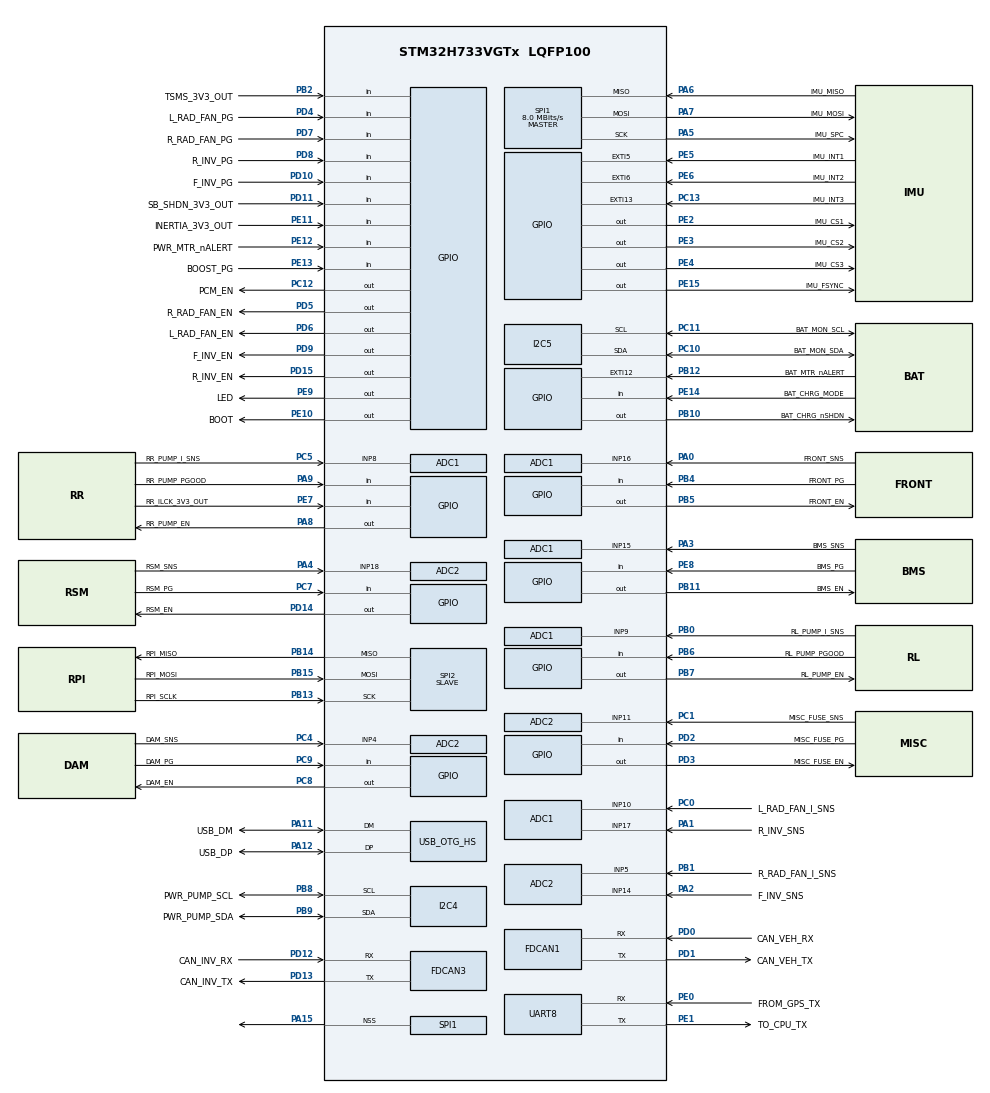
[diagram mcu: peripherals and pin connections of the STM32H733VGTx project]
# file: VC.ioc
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ADC1.Channel-1\#ChannelRegularConversion=ADC_CHANNEL_8
ADC1.Channel-2\#ChannelRegularConversion=ADC_CHANNEL_9
ADC1.Channel-3\#ChannelRegularConversion=ADC_CHANNEL_10
ADC1.Channel-4\#ChannelRegularConversion=ADC_CHANNEL_15
ADC1.Channel-5\#ChannelRegularConversion=ADC_CHANNEL_16
ADC1.Channel-6\#ChannelRegularConversion=ADC_CHANNEL_17
ADC1.ClockPrescaler=ADC_CLOCK_ASYNC_DIV4
ADC1.ConversionDataManagement=ADC_CONVERSIONDATA_DMA_CIRCULAR
ADC1.EOCSelection=ADC_EOC_SINGLE_CONV
ADC1.ExternalTrigConv=ADC_EXTERNALTRIG_T3_TRGO
ADC1.NbrOfConversion=6
ADC1.NbrOfConversionFlag=1
ADC1.OffsetNumber-1\#ChannelRegularConversion=ADC_OFFSET_NONE
ADC1.OffsetNumber-2\#ChannelRegularConversion=ADC_OFFSET_NONE
ADC1.OffsetNumber-3\#ChannelRegularConversion=ADC_OFFSET_NONE
ADC1.OffsetNumber-4\#ChannelRegularConversion=ADC_OFFSET_NONE
ADC1.OffsetNumber-5\#ChannelRegularConversion=ADC_OFFSET_NONE
ADC1.OffsetNumber-6\#ChannelRegularConversion=ADC_OFFSET_NONE
ADC1.OffsetSignedSaturation-1\#ChannelRegularConversion=DISABLE
ADC1.OffsetSignedSaturation-2\#ChannelRegularConversion=DISABLE
ADC1.OffsetSignedSaturation-3\#ChannelRegularConversion=DISABLE
ADC1.OffsetSignedSaturation-4\#ChannelRegularConversion=DISABLE
ADC1.OffsetSignedSaturation-5\#ChannelRegularConversion=DISABLE
ADC1.OffsetSignedSaturation-6\#ChannelRegularConversion=DISABLE
ADC1.Rank-1\#ChannelRegularConversion=1
ADC1.Rank-2\#ChannelRegularConversion=2
ADC1.Rank-3\#ChannelRegularConversion=3
ADC1.Rank-4\#ChannelRegularConversion=4
ADC1.Rank-5\#ChannelRegularConversion=5
ADC1.Rank-6\#ChannelRegularConversion=6
ADC1.SamplingTime-1\#ChannelRegularConversion=ADC_SAMPLETIME_32CYCLES_5
ADC1.SamplingTime-2\#ChannelRegularConversion=ADC_SAMPLETIME_32CYCLES_5
ADC1.SamplingTime-3\#ChannelRegularConversion=ADC_SAMPLETIME_32CYCLES_5
ADC1.SamplingTime-4\#ChannelRegularConversion=ADC_SAMPLETIME_32CYCLES_5
ADC1.SamplingTime-5\#ChannelRegularConversion=ADC_SAMPLETIME_32CYCLES_5
ADC1.SamplingTime-6\#ChannelRegularConversion=ADC_SAMPLETIME_32CYCLES_5
ADC1.master=1
ADC2.Channel-1\#ChannelRegularConversion=ADC_CHANNEL_4
ADC2.Channel-2\#ChannelRegularConversion=ADC_CHANNEL_5
ADC2.Channel-3\#ChannelRegularConversion=ADC_CHANNEL_11
ADC2.Channel-4\#ChannelRegularConversion=ADC_CHANNEL_14
ADC2.Channel-5\#ChannelRegularConversion=ADC_CHANNEL_18
ADC2.ClockPrescaler=ADC_CLOCK_ASYNC_DIV4
ADC2.ConversionDataManagement=ADC_CONVERSIONDATA_DMA_CIRCULAR
ADC2.EOCSelection=ADC_EOC_SEQ_CONV
ADC2.ExternalTrigConv=ADC_EXTERNALTRIG_T3_TRGO
ADC2.NbrOfConversion=5
ADC2.NbrOfConversionFlag=1
ADC2.OffsetNumber-1\#ChannelRegularConversion=ADC_OFFSET_NONE
ADC2.OffsetNumber-2\#ChannelRegularConversion=ADC_OFFSET_NONE
ADC2.OffsetNumber-3\#ChannelRegularConversion=ADC_OFFSET_NONE
ADC2.OffsetNumber-4\#ChannelRegularConversion=ADC_OFFSET_NONE
ADC2.OffsetNumber-5\#ChannelRegularConversion=ADC_OFFSET_NONE
ADC2.OffsetSignedSaturation-1\#ChannelRegularConversion=DISABLE
ADC2.OffsetSignedSaturation-2\#ChannelRegularConversion=DISABLE
ADC2.OffsetSignedSaturation-3\#ChannelRegularConversion=DISABLE
ADC2.OffsetSignedSaturation-4\#ChannelRegularConversion=DISABLE
ADC2.OffsetSignedSaturation-5\#ChannelRegularConversion=DISABLE
ADC2.Rank-1\#ChannelRegularConversion=1
ADC2.Rank-2\#ChannelRegularConversion=2
ADC2.Rank-3\#ChannelRegularConversion=3
ADC2.Rank-4\#ChannelRegularConversion=4
ADC2.Rank-5\#ChannelRegularConversion=5
ADC2.SamplingTime-1\#ChannelRegularConversion=ADC_SAMPLETIME_32CYCLES_5
ADC2.SamplingTime-2\#ChannelRegularConversion=ADC_SAMPLETIME_32CYCLES_5
ADC2.SamplingTime-3\#ChannelRegularConversion=ADC_SAMPLETIME_32CYCLES_5
ADC2.SamplingTime-4\#ChannelRegularConversion=ADC_SAMPLETIME_32CYCLES_5
ADC2.SamplingTime-5\#ChannelRegularConversion=ADC_SAMPLETIME_32CYCLES_5
CORTEX_M7.CPU_ICache=Enabled
Dma.ADC1.0.Direction=DMA_PERIPH_TO_MEMORY
Dma.ADC1.0.EventEnable=DISABLE
Dma.ADC1.0.FIFOMode=DMA_FIFOMODE_DISABLE
Dma.ADC1.0.Instance=DMA1_Stream1
Dma.ADC1.0.MemDataAlignment=DMA_MDATAALIGN_HALFWORD
Dma.ADC1.0.MemInc=DMA_MINC_ENABLE
Dma.ADC1.0.Mode=DMA_CIRCULAR
Dma.ADC1.0.PeriphDataAlignment=DMA_PDATAALIGN_HALFWORD
Dma.ADC1.0.PeriphInc=DMA_PINC_DISABLE
Dma.ADC1.0.Polarity=HAL_DMAMUX_REQ_GEN_RISING
Dma.ADC1.0.Priority=DMA_PRIORITY_LOW
Dma.ADC1.0.RequestNumber=1
Dma.ADC1.0.SignalID=NONE
Dma.ADC1.0.SyncEnable=DISABLE
Dma.ADC1.0.SyncPolarity=HAL_DMAMUX_SYNC_NO_EVENT
Dma.ADC1.0.SyncRequestNumber=1
Dma.ADC1.0.SyncSignalID=NONE
Dma.ADC2.1.Direction=DMA_PERIPH_TO_MEMORY
Dma.ADC2.1.EventEnable=DISABLE
Dma.ADC2.1.FIFOMode=DMA_FIFOMODE_DISABLE
Dma.ADC2.1.Instance=DMA1_Stream2
Dma.ADC2.1.MemDataAlignment=DMA_MDATAALIGN_HALFWORD
Dma.ADC2.1.MemInc=DMA_MINC_ENABLE
Dma.ADC2.1.Mode=DMA_CIRCULAR
Dma.ADC2.1.PeriphDataAlignment=DMA_PDATAALIGN_HALFWORD
Dma.ADC2.1.PeriphInc=DMA_PINC_DISABLE
Dma.ADC2.1.Polarity=HAL_DMAMUX_REQ_GEN_RISING
Dma.ADC2.1.Priority=DMA_PRIORITY_LOW
Dma.ADC2.1.RequestNumber=1
Dma.ADC2.1.SignalID=NONE
Dma.ADC2.1.SyncEnable=DISABLE
Dma.ADC2.1.SyncPolarity=HAL_DMAMUX_SYNC_NO_EVENT
Dma.ADC2.1.SyncRequestNumber=1
Dma.ADC2.1.SyncSignalID=NONE
Dma.Request0=ADC1
Dma.Request1=ADC2
Dma.Request2=UART8_RX
Dma.Request3=SPI1_RX
Dma.Request4=SPI1_TX
Dma.SPI1_RX.3.Direction=DMA_PERIPH_TO_MEMORY
Dma.SPI1_RX.3.EventEnable=DISABLE
Dma.SPI1_RX.3.FIFOMode=DMA_FIFOMODE_DISABLE
Dma.SPI1_RX.3.Instance=DMA1_Stream0
Dma.SPI1_RX.3.MemDataAlignment=DMA_MDATAALIGN_BYTE
Dma.SPI1_RX.3.MemInc=DMA_MINC_ENABLE
Dma.SPI1_RX.3.Mode=DMA_NORMAL
Dma.SPI1_RX.3.PeriphDataAlignment=DMA_PDATAALIGN_BYTE
Dma.SPI1_RX.3.PeriphInc=DMA_PINC_DISABLE
Dma.SPI1_RX.3.Polarity=HAL_DMAMUX_REQ_GEN_RISING
Dma.SPI1_RX.3.Priority=DMA_PRIORITY_HIGH
Dma.SPI1_RX.3.RequestNumber=1
Dma.SPI1_RX.3.SignalID=NONE
Dma.SPI1_RX.3.SyncEnable=DISABLE
Dma.SPI1_RX.3.SyncPolarity=HAL_DMAMUX_SYNC_NO_EVENT
Dma.SPI1_RX.3.SyncRequestNumber=1
Dma.SPI1_RX.3.SyncSignalID=NONE
Dma.SPI1_TX.4.Direction=DMA_MEMORY_TO_PERIPH
Dma.SPI1_TX.4.EventEnable=DISABLE
Dma.SPI1_TX.4.FIFOMode=DMA_FIFOMODE_DISABLE
Dma.SPI1_TX.4.Instance=DMA1_Stream3
Dma.SPI1_TX.4.MemDataAlignment=DMA_MDATAALIGN_BYTE
Dma.SPI1_TX.4.MemInc=DMA_MINC_ENABLE
Dma.SPI1_TX.4.Mode=DMA_NORMAL
Dma.SPI1_TX.4.PeriphDataAlignment=DMA_PDATAALIGN_BYTE
Dma.SPI1_TX.4.PeriphInc=DMA_PINC_DISABLE
Dma.SPI1_TX.4.Polarity=HAL_DMAMUX_REQ_GEN_RISING
Dma.SPI1_TX.4.Priority=DMA_PRIORITY_LOW
Dma.SPI1_TX.4.RequestNumber=1
Dma.SPI1_TX.4.SignalID=NONE
Dma.SPI1_TX.4.SyncEnable=DISABLE
Dma.SPI1_TX.4.SyncPolarity=HAL_DMAMUX_SYNC_NO_EVENT
Dma.SPI1_TX.4.SyncRequestNumber=1
Dma.SPI1_TX.4.SyncSignalID=NONE
Dma.UART8_RX.2.Direction=DMA_PERIPH_TO_MEMORY
Dma.UART8_RX.2.EventEnable=DISABLE
Dma.UART8_RX.2.FIFOMode=DMA_FIFOMODE_DISABLE
Dma.UART8_RX.2.Instance=DMA1_Stream5
Dma.UART8_RX.2.MemDataAlignment=DMA_MDATAALIGN_BYTE
Dma.UART8_RX.2.MemInc=DMA_MINC_ENABLE
Dma.UART8_RX.2.Mode=DMA_CIRCULAR
Dma.UART8_RX.2.PeriphDataAlignment=DMA_PDATAALIGN_BYTE
Dma.UART8_RX.2.PeriphInc=DMA_PINC_DISABLE
Dma.UART8_RX.2.Polarity=HAL_DMAMUX_REQ_GEN_RISING
Dma.UART8_RX.2.Priority=DMA_PRIORITY_LOW
Dma.UART8_RX.2.RequestNumber=1
Dma.UART8_RX.2.SignalID=NONE
Dma.UART8_RX.2.SyncEnable=DISABLE
Dma.UART8_RX.2.SyncPolarity=HAL_DMAMUX_SYNC_NO_EVENT
Dma.UART8_RX.2.SyncRequestNumber=1
Dma.UART8_RX.2.SyncSignalID=NONE
FDCAN1.AutoRetransmission=ENABLE
FDCAN1.CalculateBaudRateNominal=1000000
FDCAN1.CalculateTimeBitNominal=1000
FDCAN1.CalculateTimeQuantumNominal=62.5
FDCAN1.DataPrescaler=3
FDCAN1.DataSyncJumpWidth=2
FDCAN1.DataTimeSeg1=5
FDCAN1.DataTimeSeg2=2
FDCAN1.ExtFiltersNbr=1
FDCAN1.FrameFormat=FDCAN_FRAME_FD_NO_BRS
FDCAN1.NominalPrescaler=6
FDCAN1.NominalSyncJumpWidth=2
FDCAN1.NominalTimeSeg1=13
FDCAN1.NominalTimeSeg2=2
FDCAN1.RxBufferSize=FDCAN_DATA_BYTES_64
FDCAN1.RxFifo0ElmtSize=FDCAN_DATA_BYTES_64
FDCAN1.RxFifo0ElmtsNbr=32
FDCAN1.RxFifo1ElmtSize=FDCAN_DATA_BYTES_64
FDCAN1.StdFiltersNbr=1
FDCAN1.TxElmtSize=FDCAN_DATA_BYTES_64
FDCAN1.TxFifoQueueElmtsNbr=32
FDCAN3.AutoRetransmission=ENABLE
FDCAN3.CalculateBaudRateNominal=500000
FDCAN3.CalculateTimeBitNominal=2000
FDCAN3.CalculateTimeQuantumNominal=125.0
FDCAN3.ExtFiltersNbr=1
FDCAN3.FrameFormat=FDCAN_FRAME_CLASSIC
FDCAN3.MessageRAMOffset=1920
FDCAN3.NominalPrescaler=12
FDCAN3.NominalSyncJumpWidth=3
FDCAN3.NominalTimeSeg1=12
FDCAN3.NominalTimeSeg2=3
FDCAN3.RxFifo0ElmtsNbr=32
FDCAN3.StdFiltersNbr=1
FDCAN3.TxFifoQueueElmtsNbr=32
I2C4.Timing=0x20A0A3F6
I2C5.Timing=0x20A0A3F6
IWDG1.Reload=LSI_FREQUENCY/IWDG_PRESCALER/IWDG_RESET_FREQUENCY
Mcu.Family=STM32H7
Mcu.Name=STM32H733VGTx
Mcu.Package=LQFP100
Mcu.UserConstants=IWDG_RESET_FREQUENCY,5;IWDG_PRESCALER,4;LSI_FREQUENCY,32000;SBG_ELLIPSE_GPS_BAUD_RATE,460800;TIMx_FREQUENCY,250000000;TIM3_PRESCALER,250;ADC_FREQUENCY,1000
NVIC.ADC_IRQn=true\:5\:0\:true\:false\:true\:true\:true\:true
NVIC.DMA1_Stream0_IRQn=true\:5\:0\:true\:false\:true\:false\:true\:true
NVIC.DMA1_Stream1_IRQn=true\:5\:0\:false\:false\:true\:false\:true\:true
NVIC.DMA1_Stream2_IRQn=true\:5\:0\:false\:false\:true\:false\:true\:true
NVIC.DMA1_Stream3_IRQn=true\:5\:0\:true\:false\:true\:false\:true\:true
NVIC.DMA1_Stream5_IRQn=true\:5\:0\:true\:false\:true\:false\:true\:true
NVIC.EXTI15_10_IRQn=true\:5\:0\:true\:false\:true\:true\:true\:true
NVIC.EXTI9_5_IRQn=true\:5\:0\:true\:false\:true\:true\:true\:true
NVIC.FDCAN1_IT0_IRQn=true\:5\:0\:true\:false\:true\:true\:true\:true
NVIC.FDCAN1_IT1_IRQn=true\:5\:0\:true\:false\:true\:true\:true\:true
NVIC.FDCAN3_IT0_IRQn=true\:5\:0\:true\:false\:true\:true\:true\:true
NVIC.FDCAN3_IT1_IRQn=true\:5\:0\:true\:false\:true\:true\:true\:true
NVIC.I2C4_ER_IRQn=true\:5\:0\:true\:false\:true\:true\:true\:true
NVIC.I2C4_EV_IRQn=true\:5\:0\:true\:false\:true\:true\:true\:true
NVIC.I2C5_ER_IRQn=true\:5\:0\:true\:false\:true\:true\:true\:true
NVIC.I2C5_EV_IRQn=true\:5\:0\:true\:false\:true\:true\:true\:true
NVIC.OTG_HS_EP1_IN_IRQn=true\:5\:0\:true\:false\:true\:true\:true\:true
NVIC.OTG_HS_EP1_OUT_IRQn=true\:5\:0\:true\:false\:true\:true\:true\:true
NVIC.OTG_HS_IRQn=true\:5\:0\:true\:false\:true\:true\:true\:true
NVIC.PriorityGroup=NVIC_PRIORITYGROUP_4
NVIC.SPI1_IRQn=true\:5\:0\:true\:false\:true\:true\:true\:true
NVIC.SPI2_IRQn=true\:5\:0\:true\:false\:true\:true\:true\:true
NVIC.TIM6_DAC_IRQn=true\:15\:0\:false\:false\:true\:false\:true\:true
NVIC.TIM7_IRQn=true\:5\:0\:true\:false\:true\:true\:true\:true
NVIC.TimeBase=TIM6_DAC_IRQn
NVIC.TimeBaseIP=TIM6
NVIC.UART8_IRQn=true\:5\:0\:true\:false\:true\:true\:true\:true
PA0.GPIO_Label=FRONT_SNS
PA0.Mode=IN16-Single-Ended
PA0.Signal=ADC1_INP16
PA1.GPIO_Label=R_INV_SNS
PA1.Mode=IN17-Single-Ended
PA1.Signal=ADC1_INP17
PA11.GPIO_Label=USB_DM
PA11.Mode=Device_Only_FS
PA11.Signal=USB_OTG_HS_DM
PA12.GPIO_Label=USB_DP
PA12.Mode=Device_Only_FS
PA12.Signal=USB_OTG_HS_DP
PA13(JTMS/SWDIO).Signal=DEBUG_JTMS-SWDIO
PA14(JTCK/SWCLK).Signal=DEBUG_JTCK-SWCLK
PA15(JTDI).Mode=NSS_Signal_Hard_Output
PA15(JTDI).Signal=SPI1_NSS
PA2.GPIO_Label=F_INV_SNS
PA2.Signal=ADCx_INP14
PA3.GPIO_Label=BMS_SNS
PA3.Signal=ADCx_INP15
PA4.GPIO_Label=RSM_SNS
PA4.Signal=ADCx_INP18
PA5.GPIO_Label=IMU_SPC
PA5.Mode=Full_Duplex_Master
PA5.Signal=SPI1_SCK
PA6.GPIO_Label=IMU_MISO
PA6.Mode=Full_Duplex_Master
PA6.Signal=SPI1_MISO
PA7.GPIO_Label=IMU_MOSI
PA7.Mode=Full_Duplex_Master
PA7.Signal=SPI1_MOSI
PA8.GPIO_Label=RR_PUMP_EN
PA8.GPIO_ModeDefaultOutputPP=GPIO_MODE_OUTPUT_OD
PA8.GPIO_PuPd=GPIO_NOPULL
PA8.Signal=GPIO_Output
PA9.GPIO_Label=RR_PUMP_PGOOD
PA9.Signal=GPIO_Input
PB0.GPIO_Label=RL_PUMP_I_SNS
PB0.Signal=ADCx_INP9
PB1.GPIO_Label=R_RAD_FAN_I_SNS
PB1.Signal=ADCx_INP5
PB10.GPIO_Label=BAT_CHRG_nSHDN
PB10.Signal=GPIO_Output
PB11.GPIO_Label=BMS_EN
PB11.Signal=GPIO_Output
PB12.GPIO_Label=BAT_MTR_nALERT
PB12.Signal=GPXTI12
PB13.GPIO_Label=RPI_SCLK
PB13.Mode=Full_Duplex_Slave
PB13.Signal=SPI2_SCK
PB14.GPIO_Label=RPI_MISO
PB14.Mode=Full_Duplex_Slave
PB14.Signal=SPI2_MISO
PB15.GPIO_Label=RPI_MOSI
PB15.Mode=Full_Duplex_Slave
PB15.Signal=SPI2_MOSI
PB2.GPIO_Label=TSMS_3V3_OUT
PB2.Signal=GPIO_Input
PB3(JTDO/TRACESWO).Signal=DEBUG_JTDO-SWO
PB4(NJTRST).GPIO_Label=FRONT_PG
PB4(NJTRST).Signal=GPIO_Input
PB5.GPIO_Label=FRONT_EN
PB5.Signal=GPIO_Output
PB6.GPIO_Label=RL_PUMP_PGOOD
PB6.Signal=GPIO_Input
PB7.GPIO_Label=RL_PUMP_EN
PB7.GPIO_ModeDefaultOutputPP=GPIO_MODE_OUTPUT_OD
PB7.GPIO_PuPd=GPIO_NOPULL
PB7.Signal=GPIO_Output
PB8.GPIO_Label=PWR_PUMP_SCL
PB8.Mode=I2C
PB8.Signal=I2C4_SCL
PB9.GPIO_Label=PWR_PUMP_SDA
PB9.Mode=I2C
PB9.Signal=I2C4_SDA
PC0.GPIO_Label=L_RAD_FAN_I_SNS
PC0.Signal=ADCx_INP10
PC1.GPIO_Label=MISC_FUSE_SNS
PC1.Signal=ADCx_INP11
PC10.GPIO_Label=BAT_MON_SDA
PC10.Mode=I2C
PC10.Signal=I2C5_SDA
PC11.GPIO_Label=BAT_MON_SCL
PC11.Mode=I2C
PC11.Signal=I2C5_SCL
PC12.GPIO_Label=PCM_EN
PC12.Signal=GPIO_Output
PC13.GPIO_Label=IMU_INT3
PC13.Signal=GPXTI13
PC14-OSC32_IN.GPIO_Label=OSC32_IN
PC14-OSC32_IN.Signal=RCC_OSC32_IN
PC15-OSC32_OUT.GPIO_Label=OSC32_OUT
PC15-OSC32_OUT.Signal=RCC_OSC32_OUT
PC4.GPIO_Label=DAM_SNS
PC4.Signal=ADCx_INP4
PC5.GPIO_Label=RR_PUMP_I_SNS
PC5.Signal=ADCx_INP8
PC7.GPIO_Label=RSM_PG
PC7.Signal=GPIO_Input
PC8.GPIO_Label=DAM_EN
PC8.Signal=GPIO_Output
PC9.GPIO_Label=DAM_PG
PC9.Signal=GPIO_Input
PD0.GPIO_Label=CAN_VEH_RX
PD0.Mode=FDCAN_Activate
PD0.Signal=FDCAN1_RX
PD1.GPIO_Label=CAN_VEH_TX
PD1.Mode=FDCAN_Activate
PD1.Signal=FDCAN1_TX
PD10.GPIO_Label=F_INV_PG
PD10.Signal=GPIO_Input
PD11.GPIO_Label=SB_SHDN_3V3_OUT
PD11.Signal=GPIO_Input
PD12.GPIO_Label=CAN_INV_RX
PD12.Mode=FDCAN_Activate
PD12.Signal=FDCAN3_RX
PD13.GPIO_Label=CAN_INV_TX
PD13.Mode=FDCAN_Activate
PD13.Signal=FDCAN3_TX
PD14.GPIO_Label=RSM_EN
PD14.Signal=GPIO_Output
PD15.GPIO_Label=R_INV_EN
PD15.Signal=GPIO_Output
PD2.GPIO_Label=MISC_FUSE_PG
PD2.Signal=GPIO_Input
PD3.GPIO_Label=MISC_FUSE_EN
PD3.Signal=GPIO_Output
PD4.GPIO_Label=L_RAD_FAN_PG
PD4.Signal=GPIO_Input
PD5.GPIO_Label=R_RAD_FAN_EN
PD5.Signal=GPIO_Output
PD6.GPIO_Label=L_RAD_FAN_EN
PD6.Signal=GPIO_Output
PD7.GPIO_Label=R_RAD_FAN_PG
PD7.Signal=GPIO_Input
PD8.GPIO_Label=R_INV_PG
PD8.Signal=GPIO_Input
PD9.GPIO_Label=F_INV_EN
PD9.Signal=GPIO_Output
PE0.GPIO_Label=FROM_GPS_TX
PE0.Mode=Asynchronous
PE0.Signal=UART8_RX
PE1.GPIO_Label=TO_CPU_TX
PE1.Mode=Asynchronous
PE1.Signal=UART8_TX
PE10.GPIO_Label=BOOT
PE10.Signal=GPIO_Output
PE11.GPIO_Label=INERTIA_3V3_OUT
PE11.Signal=GPIO_Input
PE12.GPIO_Label=PWR_MTR_nALERT
PE12.Signal=GPIO_Input
PE13.GPIO_Label=BOOST_PG
PE13.Signal=GPIO_Input
PE14.GPIO_Label=BAT_CHRG_MODE
PE14.Signal=GPIO_Input
PE15.GPIO_Label=IMU_FSYNC
PE15.Signal=GPIO_Output
PE2.GPIO_Label=IMU_CS1
PE2.Signal=GPIO_Output
PE3.GPIO_Label=IMU_CS2
PE3.Signal=GPIO_Output
PE4.GPIO_Label=IMU_CS3
PE4.Signal=GPIO_Output
PE5.GPIO_Label=IMU_INT1
PE5.Signal=GPXTI5
PE6.GPIO_Label=IMU_INT2
PE6.Signal=GPXTI6
PE7.GPIO_Label=RR_ILCK_3V3_OUT
PE7.Signal=GPIO_Input
PE8.GPIO_Label=BMS_PG
PE8.Signal=GPIO_Input
PE9.GPIO_Label=LED
PE9.Signal=GPIO_Output
PH0-OSC_IN.GPIO_Label=OSC_IN
PH0-OSC_IN.Mode=HSE-External-Oscillator
PH0-OSC_IN.Signal=RCC_OSC_IN
PH1-OSC_OUT.GPIO_Label=OSC_OUT
PH1-OSC_OUT.Mode=HSE-External-Oscillator
PH1-OSC_OUT.Signal=RCC_OSC_OUT
ProjectManager.HeapSize=0x200
ProjectManager.StackSize=0x400
ProjectManager.TargetToolchain=EWARM V8.50
RCC.ADCFreq_Value=96000000
RCC.APB1Freq_Value=125000000
RCC.APB2Freq_Value=125000000
RCC.APB3Freq_Value=125000000
RCC.APB4Freq_Value=125000000
RCC.CKPERSourceSelection=RCC_CLKPSOURCE_HSE
RCC.CortexFreq_Value=250000000
RCC.D1PPRE=RCC_APB3_DIV2
RCC.D2PPRE1=RCC_APB1_DIV2
RCC.D2PPRE2=RCC_APB2_DIV2
RCC.D3PPRE=RCC_APB4_DIV2
RCC.DIVM1=1
RCC.DIVM2=1
RCC.DIVM3=1
RCC.DIVN1=31
RCC.DIVN2=24
RCC.DIVN3=24
RCC.DIVP1=1
RCC.DIVP3=12
RCC.DIVQ1=1
RCC.DIVR3=4
RCC.FDCANCLockSelection=RCC_FDCANCLKSOURCE_PLL2
RCC.HCLKFreq_Value=250000000
RCC.HSE_VALUE=8000000
RCC.LSE_VALUE=32.77
RCC.PLL2FRACN=0
RCC.PLL2_VCI_Range-AdvancedSettings=RCC_PLL2VCIRANGE_3
RCC.PLL3FRACN=0
RCC.PLLFRACN=2048
RCC.PLLSourceVirtual=RCC_PLLSOURCE_HSE
RCC.SPI123CLockSelection=RCC_SPI123CLKSOURCE_PLL3
RCC.SYSCLKFreq_VALUE=250000000
RCC.SYSCLKSource=RCC_SYSCLKSOURCE_PLLCLK
RCC.USBCLockSelection=RCC_USBCLKSOURCE_HSI48
RCC.USBFreq_Value=48000000
SH.ADCx_INP10.0=ADC1_INP10,IN10-Single-Ended
SH.ADCx_INP11.0=ADC2_INP11,IN11-Single-Ended
SH.ADCx_INP14.0=ADC2_INP14,IN14-Single-Ended
SH.ADCx_INP15.0=ADC1_INP15,IN15-Single-Ended
SH.ADCx_INP18.0=ADC2_INP18,IN18-Single-Ended
SH.ADCx_INP4.0=ADC2_INP4,IN4-Single-Ended
SH.ADCx_INP5.0=ADC2_INP5,IN5-Single-Ended
SH.ADCx_INP8.0=ADC1_INP8,IN8-Single-Ended
SH.ADCx_INP9.0=ADC1_INP9,IN9-Single-Ended
SPI1.CalculateBaudRate=8.0 MBits/s
SPI1.DataSize=SPI_DATASIZE_8BIT
SPI1.Direction=SPI_DIRECTION_2LINES
SPI1.Mode=SPI_MODE_MASTER
SPI1.VirtualNSS=VM_NSSHARD
SPI1.VirtualType=VM_MASTER
SPI2.Direction=SPI_DIRECTION_2LINES
SPI2.Mode=SPI_MODE_SLAVE
SPI2.VirtualType=VM_SLAVE
TIM3.Channel-Output\ Compare1\ No\ Output=TIM_CHANNEL_1
TIM3.Period=(TIMx_FREQUENCY / TIM3_PRESCALER / ADC_FREQUENCY) - 1
TIM3.Prescaler=TIM3_PRESCALER - 1
TIM3.TIM_MasterOutputTrigger=TIM_TRGO_UPDATE
TIM7.Period=960-1
TIM7.Prescaler=10-1
UART8.BaudRate=SBG_ELLIPSE_GPS_BAUD_RATE
USB_OTG_HS.VirtualMode-Device_Only_FS=Device_Only_FS
VP_CORDIC_VS_CORDIC.Mode=CORDIC_Activate
VP_FMAC_VS_FMAC.Mode=FMAC_Activate
VP_IWDG1_VS_IWDG.Mode=IWDG_Activate
VP_MEMORYMAP_VS_MEMORYMAP.Mode=CurAppReg
VP_SYS_VS_tim6.Mode=TIM6
VP_TIM3_VS_no_output1.Mode=Output Compare1 No Output
VP_TIM7_VS_ClockSourceINT.Mode=Enable_Timer
board=custom

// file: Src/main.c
/* USER CODE BEGIN Header */
/**
 ******************************************************************************
 * @file           : main.c
 * @brief          : Main program body
 ******************************************************************************
 * @attention
 *
 * Copyright (c) 2025 STMicroelectronics.
 * All rights reserved.
 *
 * This software is licensed under terms that can be found in the LICENSE file
 * in the root directory of this software component.
 * If no LICENSE file comes with this software, it is provided AS-IS.
 *
 ******************************************************************************
 */
/* USER CODE END Header */
#include "main.h"

/* USER CODE BEGIN Includes */
#include "cmsis_os2.h"
#include "tasks.h"
#include "hw_error.hpp"
/* USER CODE END Includes */

ADC_HandleTypeDef hadc1;
ADC_HandleTypeDef hadc2;
DMA_HandleTypeDef hdma_adc1;
DMA_HandleTypeDef hdma_adc2;

CORDIC_HandleTypeDef hcordic;

FDCAN_HandleTypeDef hfdcan1;
FDCAN_HandleTypeDef hfdcan3;

FMAC_HandleTypeDef hfmac;

I2C_HandleTypeDef hi2c4;
I2C_HandleTypeDef hi2c5;

IWDG_HandleTypeDef hiwdg1;

SPI_HandleTypeDef hspi1;
SPI_HandleTypeDef hspi2;
DMA_HandleTypeDef hdma_spi1_rx;
DMA_HandleTypeDef hdma_spi1_tx;

TIM_HandleTypeDef htim3;
TIM_HandleTypeDef htim7;

UART_HandleTypeDef huart8;
DMA_HandleTypeDef  hdma_uart8_rx;

PCD_HandleTypeDef hpcd_USB_OTG_HS;

void        SystemClock_Config(void);
void        PeriphCommonClock_Config(void);
static void MX_GPIO_Init(void);
static void MX_DMA_Init(void);
static void MX_ADC1_Init(void);
static void MX_USB_OTG_HS_PCD_Init(void);
static void MX_ADC2_Init(void);
static void MX_FDCAN1_Init(void);
static void MX_FDCAN3_Init(void);
static void MX_I2C4_Init(void);
static void MX_SPI1_Init(void);
static void MX_SPI2_Init(void);
static void MX_I2C5_Init(void);
static void MX_UART8_Init(void);
static void MX_TIM3_Init(void);
static void MX_FMAC_Init(void);
static void MX_IWDG1_Init(void);
static void MX_TIM7_Init(void);
static void MX_CORDIC_Init(void);

int main(void)
{
    /* USER CODE BEGIN 1 */
    tasks_preInit();
    /* USER CODE END 1 */

    /* Enable the CPU Cache */

    /* Enable I-Cache---------------------------------------------------------*/
    SCB_EnableICache();

    /* MCU Configuration--------------------------------------------------------*/

    /* Reset of all peripherals, Initializes the Flash interface and the Systick. */
    HAL_Init();

    /* Configure the system clock */
    SystemClock_Config();

    /* Configure the peripherals common clocks */
    PeriphCommonClock_Config();

    /* Initialize all configured peripherals */
    MX_GPIO_Init();
    MX_DMA_Init();
    MX_ADC1_Init();
    MX_USB_OTG_HS_PCD_Init();
    MX_ADC2_Init();
    MX_FDCAN1_Init();
    MX_FDCAN3_Init();
    MX_I2C4_Init();
    MX_SPI1_Init();
    MX_SPI2_Init();
    MX_I2C5_Init();
    MX_UART8_Init();
    MX_TIM3_Init();
    MX_FMAC_Init();
    MX_IWDG1_Init();
    MX_TIM7_Init();
    MX_CORDIC_Init();
    /* USER CODE BEGIN 2 */
    HAL_GPIO_WritePin(LED_GPIO_Port, LED_Pin, GPIO_PIN_RESET);
    ;
    tasks_init();
    /* USER CODE END 2 */

    /* Infinite loop */
    while (1)
    {

    }
}

void SystemClock_Config(void)
{
    RCC_OscInitTypeDef RCC_OscInitStruct = { 0 };
    RCC_ClkInitTypeDef RCC_ClkInitStruct = { 0 };

    /** Supply configuration update enable
     */
    HAL_PWREx_ConfigSupply(PWR_LDO_SUPPLY);

    /** Configure the main internal regulator output voltage
     */
    __HAL_PWR_VOLTAGESCALING_CONFIG(PWR_REGULATOR_VOLTAGE_SCALE0);

    while (!__HAL_PWR_GET_FLAG(PWR_FLAG_VOSRDY))
    {
    }

    /** Initializes the RCC Oscillators according to the specified parameters
     * in the RCC_OscInitTypeDef structure.
     */
    RCC_OscInitStruct.OscillatorType = RCC_OSCILLATORTYPE_HSI48 | RCC_OSCILLATORTYPE_LSI | RCC_OSCILLATORTYPE_HSE;
    RCC_OscInitStruct.HSEState       = RCC_HSE_ON;
    RCC_OscInitStruct.LSIState       = RCC_LSI_ON;
    RCC_OscInitStruct.HSI48State     = RCC_HSI48_ON;
    RCC_OscInitStruct.PLL.PLLState   = RCC_PLL_ON;
    RCC_OscInitStruct.PLL.PLLSource  = RCC_PLLSOURCE_HSE;
    RCC_OscInitStruct.PLL.PLLM       = 1;
    RCC_OscInitStruct.PLL.PLLN       = 31;
    RCC_OscInitStruct.PLL.PLLP       = 1;
    RCC_OscInitStruct.PLL.PLLQ       = 1;
    RCC_OscInitStruct.PLL.PLLR       = 2;
    RCC_OscInitStruct.PLL.PLLRGE     = RCC_PLL1VCIRANGE_3;
    RCC_OscInitStruct.PLL.PLLVCOSEL  = RCC_PLL1VCOWIDE;
    RCC_OscInitStruct.PLL.PLLFRACN   = 2048;
    if (HAL_RCC_OscConfig(&RCC_OscInitStruct) != HAL_OK)
    {
        Error_Handler();
    }

    /** Initializes the CPU, AHB and APB buses clocks
     */
    RCC_ClkInitStruct.ClockType = RCC_CLOCKTYPE_HCLK | RCC_CLOCKTYPE_SYSCLK | RCC_CLOCKTYPE_PCLK1 |
                                  RCC_CLOCKTYPE_PCLK2 | RCC_CLOCKTYPE_D3PCLK1 | RCC_CLOCKTYPE_D1PCLK1;
    RCC_ClkInitStruct.SYSCLKSource   = RCC_SYSCLKSOURCE_PLLCLK;
    RCC_ClkInitStruct.SYSCLKDivider  = RCC_SYSCLK_DIV1;
    RCC_ClkInitStruct.AHBCLKDivider  = RCC_HCLK_DIV1;
    RCC_ClkInitStruct.APB3CLKDivider = RCC_APB3_DIV2;
    RCC_ClkInitStruct.APB1CLKDivider = RCC_APB1_DIV2;
    RCC_ClkInitStruct.APB2CLKDivider = RCC_APB2_DIV2;
    RCC_ClkInitStruct.APB4CLKDivider = RCC_APB4_DIV2;

    if (HAL_RCC_ClockConfig(&RCC_ClkInitStruct, FLASH_LATENCY_3) != HAL_OK)
    {
        Error_Handler();
    }
}

void PeriphCommonClock_Config(void)
{
    RCC_PeriphCLKInitTypeDef PeriphClkInitStruct = { 0 };

    /** Initializes the peripherals clock
     */
    PeriphClkInitStruct.PeriphClockSelection =
        RCC_PERIPHCLK_ADC | RCC_PERIPHCLK_SPI2 | RCC_PERIPHCLK_SPI1 | RCC_PERIPHCLK_FDCAN;
    PeriphClkInitStruct.PLL2.PLL2M           = 1;
    PeriphClkInitStruct.PLL2.PLL2N           = 24;
    PeriphClkInitStruct.PLL2.PLL2P           = 2;
    PeriphClkInitStruct.PLL2.PLL2Q           = 2;
    PeriphClkInitStruct.PLL2.PLL2R           = 2;
    PeriphClkInitStruct.PLL2.PLL2RGE         = RCC_PLL2VCIRANGE_3;
    PeriphClkInitStruct.PLL2.PLL2VCOSEL      = RCC_PLL2VCOWIDE;
    PeriphClkInitStruct.PLL2.PLL2FRACN       = 0;
    PeriphClkInitStruct.PLL3.PLL3M           = 1;
    PeriphClkInitStruct.PLL3.PLL3N           = 24;
    PeriphClkInitStruct.PLL3.PLL3P           = 12;
    PeriphClkInitStruct.PLL3.PLL3Q           = 2;
    PeriphClkInitStruct.PLL3.PLL3R           = 4;
    PeriphClkInitStruct.PLL3.PLL3RGE         = RCC_PLL3VCIRANGE_3;
    PeriphClkInitStruct.PLL3.PLL3VCOSEL      = RCC_PLL3VCOWIDE;
    PeriphClkInitStruct.PLL3.PLL3FRACN       = 0;
    PeriphClkInitStruct.Spi123ClockSelection = RCC_SPI123CLKSOURCE_PLL3;
    PeriphClkInitStruct.FdcanClockSelection  = RCC_FDCANCLKSOURCE_PLL2;
    PeriphClkInitStruct.AdcClockSelection    = RCC_ADCCLKSOURCE_PLL2;
    if (HAL_RCCEx_PeriphCLKConfig(&PeriphClkInitStruct) != HAL_OK)
    {
        Error_Handler();
    }
}

static void MX_ADC1_Init(void)
{

    ADC_MultiModeTypeDef   multimode = { 0 };
    ADC_ChannelConfTypeDef sConfig   = { 0 };

    /** Common config
     */
    hadc1.Instance                      = ADC1;
    hadc1.Init.ClockPrescaler           = ADC_CLOCK_ASYNC_DIV4;
    hadc1.Init.Resolution               = ADC_RESOLUTION_16B;
    hadc1.Init.ScanConvMode             = ADC_SCAN_ENABLE;
    hadc1.Init.EOCSelection             = ADC_EOC_SINGLE_CONV;
    hadc1.Init.LowPowerAutoWait         = DISABLE;
    hadc1.Init.ContinuousConvMode       = DISABLE;
    hadc1.Init.NbrOfConversion          = 6;
    hadc1.Init.DiscontinuousConvMode    = DISABLE;
    hadc1.Init.ExternalTrigConv         = ADC_EXTERNALTRIG_T3_TRGO;
    hadc1.Init.ExternalTrigConvEdge     = ADC_EXTERNALTRIGCONVEDGE_RISING;
    hadc1.Init.ConversionDataManagement = ADC_CONVERSIONDATA_DMA_CIRCULAR;
    hadc1.Init.Overrun                  = ADC_OVR_DATA_PRESERVED;
    hadc1.Init.LeftBitShift             = ADC_LEFTBITSHIFT_NONE;
    hadc1.Init.OversamplingMode         = DISABLE;
    hadc1.Init.Oversampling.Ratio       = 1;
    if (HAL_ADC_Init(&hadc1) != HAL_OK)
    {
        Error_Handler();
    }

    /** Configure the ADC multi-mode
     */
    multimode.Mode = ADC_MODE_INDEPENDENT;
    if (HAL_ADCEx_MultiModeConfigChannel(&hadc1, &multimode) != HAL_OK)
    {
        Error_Handler();
    }

    /** Configure Regular Channel
     */
    sConfig.Channel                = ADC_CHANNEL_8;
    sConfig.Rank                   = ADC_REGULAR_RANK_1;
    sConfig.SamplingTime           = ADC_SAMPLETIME_32CYCLES_5;
    sConfig.SingleDiff             = ADC_SINGLE_ENDED;
    sConfig.OffsetNumber           = ADC_OFFSET_NONE;
    sConfig.Offset                 = 0;
    sConfig.OffsetSignedSaturation = DISABLE;
    if (HAL_ADC_ConfigChannel(&hadc1, &sConfig) != HAL_OK)
    {
        Error_Handler();
    }

    /** Configure Regular Channel
     */
    sConfig.Channel = ADC_CHANNEL_9;
    sConfig.Rank    = ADC_REGULAR_RANK_2;
    if (HAL_ADC_ConfigChannel(&hadc1, &sConfig) != HAL_OK)
    {
        Error_Handler();
    }

    /** Configure Regular Channel
     */
    sConfig.Channel = ADC_CHANNEL_10;
    sConfig.Rank    = ADC_REGULAR_RANK_3;
    if (HAL_ADC_ConfigChannel(&hadc1, &sConfig) != HAL_OK)
    {
        Error_Handler();
    }

    /** Configure Regular Channel
     */
    sConfig.Channel = ADC_CHANNEL_15;
    sConfig.Rank    = ADC_REGULAR_RANK_4;
    if (HAL_ADC_ConfigChannel(&hadc1, &sConfig) != HAL_OK)
    {
        Error_Handler();
    }

    /** Configure Regular Channel
     */
    sConfig.Channel = ADC_CHANNEL_16;
    sConfig.Rank    = ADC_REGULAR_RANK_5;
    if (HAL_ADC_ConfigChannel(&hadc1, &sConfig) != HAL_OK)
    {
        Error_Handler();
    }

    /** Configure Regular Channel
     */
    sConfig.Channel = ADC_CHANNEL_17;
    sConfig.Rank    = ADC_REGULAR_RANK_6;
    if (HAL_ADC_ConfigChannel(&hadc1, &sConfig) != HAL_OK)
    {
        Error_Handler();
    }
}

static void MX_ADC2_Init(void)
{

    ADC_ChannelConfTypeDef sConfig = { 0 };

    /** Common config
     */
    hadc2.Instance                      = ADC2;
    hadc2.Init.ClockPrescaler           = ADC_CLOCK_ASYNC_DIV4;
    hadc2.Init.Resolution               = ADC_RESOLUTION_16B;
    hadc2.Init.ScanConvMode             = ADC_SCAN_ENABLE;
    hadc2.Init.EOCSelection             = ADC_EOC_SEQ_CONV;
    hadc2.Init.LowPowerAutoWait         = DISABLE;
    hadc2.Init.ContinuousConvMode       = DISABLE;
    hadc2.Init.NbrOfConversion          = 5;
    hadc2.Init.DiscontinuousConvMode    = DISABLE;
    hadc2.Init.ExternalTrigConv         = ADC_EXTERNALTRIG_T3_TRGO;
    hadc2.Init.ExternalTrigConvEdge     = ADC_EXTERNALTRIGCONVEDGE_RISING;
    hadc2.Init.ConversionDataManagement = ADC_CONVERSIONDATA_DMA_CIRCULAR;
    hadc2.Init.Overrun                  = ADC_OVR_DATA_PRESERVED;
    hadc2.Init.LeftBitShift             = ADC_LEFTBITSHIFT_NONE;
    hadc2.Init.OversamplingMode         = DISABLE;
    hadc2.Init.Oversampling.Ratio       = 1;
    if (HAL_ADC_Init(&hadc2) != HAL_OK)
    {
        Error_Handler();
    }

    /** Configure Regular Channel
     */
    sConfig.Channel                = ADC_CHANNEL_4;
    sConfig.Rank                   = ADC_REGULAR_RANK_1;
    sConfig.SamplingTime           = ADC_SAMPLETIME_32CYCLES_5;
    sConfig.SingleDiff             = ADC_SINGLE_ENDED;
    sConfig.OffsetNumber           = ADC_OFFSET_NONE;
    sConfig.Offset                 = 0;
    sConfig.OffsetSignedSaturation = DISABLE;
    if (HAL_ADC_ConfigChannel(&hadc2, &sConfig) != HAL_OK)
    {
        Error_Handler();
    }

    /** Configure Regular Channel
     */
    sConfig.Channel = ADC_CHANNEL_5;
    sConfig.Rank    = ADC_REGULAR_RANK_2;
    if (HAL_ADC_ConfigChannel(&hadc2, &sConfig) != HAL_OK)
    {
        Error_Handler();
    }

    /** Configure Regular Channel
     */
    sConfig.Channel = ADC_CHANNEL_11;
    sConfig.Rank    = ADC_REGULAR_RANK_3;
    if (HAL_ADC_ConfigChannel(&hadc2, &sConfig) != HAL_OK)
    {
        Error_Handler();
    }

    /** Configure Regular Channel
     */
    sConfig.Channel = ADC_CHANNEL_14;
    sConfig.Rank    = ADC_REGULAR_RANK_4;
    if (HAL_ADC_ConfigChannel(&hadc2, &sConfig) != HAL_OK)
    {
        Error_Handler();
    }

    /** Configure Regular Channel
     */
    sConfig.Channel = ADC_CHANNEL_18;
    sConfig.Rank    = ADC_REGULAR_RANK_5;
    if (HAL_ADC_ConfigChannel(&hadc2, &sConfig) != HAL_OK)
    {
        Error_Handler();
    }
}

static void MX_CORDIC_Init(void)
{

    hcordic.Instance = CORDIC;
    if (HAL_CORDIC_Init(&hcordic) != HAL_OK)
    {
        Error_Handler();
    }
}

static void MX_FDCAN1_Init(void)
{

    hfdcan1.Instance                  = FDCAN1;
    hfdcan1.Init.FrameFormat          = FDCAN_FRAME_FD_NO_BRS;
    hfdcan1.Init.Mode                 = FDCAN_MODE_NORMAL;
    hfdcan1.Init.AutoRetransmission   = ENABLE;
    hfdcan1.Init.TransmitPause        = DISABLE;
    hfdcan1.Init.ProtocolException    = DISABLE;
    hfdcan1.Init.NominalPrescaler     = 6;
    hfdcan1.Init.NominalSyncJumpWidth = 2;
    hfdcan1.Init.NominalTimeSeg1      = 13;
    hfdcan1.Init.NominalTimeSeg2      = 2;
    hfdcan1.Init.DataPrescaler        = 3;
    hfdcan1.Init.DataSyncJumpWidth    = 2;
    hfdcan1.Init.DataTimeSeg1         = 5;
    hfdcan1.Init.DataTimeSeg2         = 2;
    hfdcan1.Init.MessageRAMOffset     = 0;
    hfdcan1.Init.StdFiltersNbr        = 1;
    hfdcan1.Init.ExtFiltersNbr        = 1;
    hfdcan1.Init.RxFifo0ElmtsNbr      = 32;
    hfdcan1.Init.RxFifo0ElmtSize      = FDCAN_DATA_BYTES_64;
    hfdcan1.Init.RxFifo1ElmtsNbr      = 0;
    hfdcan1.Init.RxFifo1ElmtSize      = FDCAN_DATA_BYTES_64;
    hfdcan1.Init.RxBuffersNbr         = 0;
    hfdcan1.Init.RxBufferSize         = FDCAN_DATA_BYTES_64;
    hfdcan1.Init.TxEventsNbr          = 0;
    hfdcan1.Init.TxBuffersNbr         = 0;
    hfdcan1.Init.TxFifoQueueElmtsNbr  = 32;
    hfdcan1.Init.TxFifoQueueMode      = FDCAN_TX_FIFO_OPERATION;
    hfdcan1.Init.TxElmtSize           = FDCAN_DATA_BYTES_64;
    if (HAL_FDCAN_Init(&hfdcan1) != HAL_OK)
    {
        Error_Handler();
    }
}

static void MX_FDCAN3_Init(void)
{

    hfdcan3.Instance                  = FDCAN3;
    hfdcan3.Init.FrameFormat          = FDCAN_FRAME_CLASSIC;
    hfdcan3.Init.Mode                 = FDCAN_MODE_NORMAL;
    hfdcan3.Init.AutoRetransmission   = ENABLE;
    hfdcan3.Init.TransmitPause        = DISABLE;
    hfdcan3.Init.ProtocolException    = DISABLE;
    hfdcan3.Init.NominalPrescaler     = 12;
    hfdcan3.Init.NominalSyncJumpWidth = 3;
    hfdcan3.Init.NominalTimeSeg1      = 12;
    hfdcan3.Init.NominalTimeSeg2      = 3;
    hfdcan3.Init.DataPrescaler        = 1;
    hfdcan3.Init.DataSyncJumpWidth    = 1;
    hfdcan3.Init.DataTimeSeg1         = 1;
    hfdcan3.Init.DataTimeSeg2         = 1;
    hfdcan3.Init.MessageRAMOffset     = 1920;
    hfdcan3.Init.StdFiltersNbr        = 1;
    hfdcan3.Init.ExtFiltersNbr        = 1;
    hfdcan3.Init.RxFifo0ElmtsNbr      = 32;
    hfdcan3.Init.RxFifo0ElmtSize      = FDCAN_DATA_BYTES_8;
    hfdcan3.Init.RxFifo1ElmtsNbr      = 0;
    hfdcan3.Init.RxFifo1ElmtSize      = FDCAN_DATA_BYTES_8;
    hfdcan3.Init.RxBuffersNbr         = 0;
    hfdcan3.Init.RxBufferSize         = FDCAN_DATA_BYTES_8;
    hfdcan3.Init.TxEventsNbr          = 0;
    hfdcan3.Init.TxBuffersNbr         = 0;
    hfdcan3.Init.TxFifoQueueElmtsNbr  = 32;
    hfdcan3.Init.TxFifoQueueMode      = FDCAN_TX_FIFO_OPERATION;
    hfdcan3.Init.TxElmtSize           = FDCAN_DATA_BYTES_8;
    if (HAL_FDCAN_Init(&hfdcan3) != HAL_OK)
    {
        Error_Handler();
    }
}

static void MX_FMAC_Init(void)
{

    hfmac.Instance = FMAC;
    if (HAL_FMAC_Init(&hfmac) != HAL_OK)
    {
        Error_Handler();
    }
}

static void MX_I2C4_Init(void)
{

    hi2c4.Instance              = I2C4;
    hi2c4.Init.Timing           = 0x20A0A3F6;
    hi2c4.Init.OwnAddress1      = 0;
    hi2c4.Init.AddressingMode   = I2C_ADDRESSINGMODE_7BIT;
    hi2c4.Init.DualAddressMode  = I2C_DUALADDRESS_DISABLE;
    hi2c4.Init.OwnAddress2      = 0;
    hi2c4.Init.OwnAddress2Masks = I2C_OA2_NOMASK;
    hi2c4.Init.GeneralCallMode  = I2C_GENERALCALL_DISABLE;
    hi2c4.Init.NoStretchMode    = I2C_NOSTRETCH_DISABLE;
    if (HAL_I2C_Init(&hi2c4) != HAL_OK)
    {
        Error_Handler();
    }

    /** Configure Analogue filter
     */
    if (HAL_I2CEx_ConfigAnalogFilter(&hi2c4, I2C_ANALOGFILTER_ENABLE) != HAL_OK)
    {
        Error_Handler();
    }

    /** Configure Digital filter
     */
    if (HAL_I2CEx_ConfigDigitalFilter(&hi2c4, 0) != HAL_OK)
    {
        Error_Handler();
    }
}

static void MX_I2C5_Init(void)
{

    hi2c5.Instance              = I2C5;
    hi2c5.Init.Timing           = 0x20A0A3F6;
    hi2c5.Init.OwnAddress1      = 0;
    hi2c5.Init.AddressingMode   = I2C_ADDRESSINGMODE_7BIT;
    hi2c5.Init.DualAddressMode  = I2C_DUALADDRESS_DISABLE;
    hi2c5.Init.OwnAddress2      = 0;
    hi2c5.Init.OwnAddress2Masks = I2C_OA2_NOMASK;
    hi2c5.Init.GeneralCallMode  = I2C_GENERALCALL_DISABLE;
    hi2c5.Init.NoStretchMode    = I2C_NOSTRETCH_DISABLE;
    if (HAL_I2C_Init(&hi2c5) != HAL_OK)
    {
        Error_Handler();
    }

    /** Configure Analogue filter
     */
    if (HAL_I2CEx_ConfigAnalogFilter(&hi2c5, I2C_ANALOGFILTER_ENABLE) != HAL_OK)
    {
        Error_Handler();
    }

    /** Configure Digital filter
     */
    if (HAL_I2CEx_ConfigDigitalFilter(&hi2c5, 0) != HAL_OK)
    {
        Error_Handler();
    }
}

static void MX_IWDG1_Init(void)
{

    /* USER CODE BEGIN IWDG1_Init 1 */
#ifndef WATCHDOG_DISABLED
    /* USER CODE END IWDG1_Init 1 */
    hiwdg1.Instance       = IWDG1;
    hiwdg1.Init.Prescaler = IWDG_PRESCALER_4;
    hiwdg1.Init.Window    = 4095;
    hiwdg1.Init.Reload    = LSI_FREQUENCY / IWDG_PRESCALER / IWDG_RESET_FREQUENCY;
    if (HAL_IWDG_Init(&hiwdg1) != HAL_OK)
    {
        Error_Handler();
    }
    /* USER CODE BEGIN IWDG1_Init 2 */
#endif
    /* USER CODE END IWDG1_Init 2 */
}

static void MX_SPI1_Init(void)
{

    /* SPI1 parameter configuration*/
    hspi1.Instance                        = SPI1;
    hspi1.Init.Mode                       = SPI_MODE_MASTER;
    hspi1.Init.Direction                  = SPI_DIRECTION_2LINES;
    hspi1.Init.DataSize                   = SPI_DATASIZE_8BIT;
    hspi1.Init.CLKPolarity                = SPI_POLARITY_LOW;
    hspi1.Init.CLKPhase                   = SPI_PHASE_1EDGE;
    hspi1.Init.NSS                        = SPI_NSS_HARD_OUTPUT;
    hspi1.Init.BaudRatePrescaler          = SPI_BAUDRATEPRESCALER_2;
    hspi1.Init.FirstBit                   = SPI_FIRSTBIT_MSB;
    hspi1.Init.TIMode                     = SPI_TIMODE_DISABLE;
    hspi1.Init.CRCCalculation             = SPI_CRCCALCULATION_DISABLE;
    hspi1.Init.CRCPolynomial              = 0x0;
    hspi1.Init.NSSPMode                   = SPI_NSS_PULSE_ENABLE;
    hspi1.Init.NSSPolarity                = SPI_NSS_POLARITY_LOW;
    hspi1.Init.FifoThreshold              = SPI_FIFO_THRESHOLD_01DATA;
    hspi1.Init.TxCRCInitializationPattern = SPI_CRC_INITIALIZATION_ALL_ZERO_PATTERN;
    hspi1.Init.RxCRCInitializationPattern = SPI_CRC_INITIALIZATION_ALL_ZERO_PATTERN;
    hspi1.Init.MasterSSIdleness           = SPI_MASTER_SS_IDLENESS_00CYCLE;
    hspi1.Init.MasterInterDataIdleness    = SPI_MASTER_INTERDATA_IDLENESS_00CYCLE;
    hspi1.Init.MasterReceiverAutoSusp     = SPI_MASTER_RX_AUTOSUSP_DISABLE;
    hspi1.Init.MasterKeepIOState          = SPI_MASTER_KEEP_IO_STATE_DISABLE;
    hspi1.Init.IOSwap                     = SPI_IO_SWAP_DISABLE;
    if (HAL_SPI_Init(&hspi1) != HAL_OK)
    {
        Error_Handler();
    }
}

static void MX_SPI2_Init(void)
{

    /* SPI2 parameter configuration*/
    hspi2.Instance                        = SPI2;
    hspi2.Init.Mode                       = SPI_MODE_SLAVE;
    hspi2.Init.Direction                  = SPI_DIRECTION_2LINES;
    hspi2.Init.DataSize                   = SPI_DATASIZE_4BIT;
    hspi2.Init.CLKPolarity                = SPI_POLARITY_LOW;
    hspi2.Init.CLKPhase                   = SPI_PHASE_1EDGE;
    hspi2.Init.NSS                        = SPI_NSS_SOFT;
    hspi2.Init.FirstBit                   = SPI_FIRSTBIT_MSB;
    hspi2.Init.TIMode                     = SPI_TIMODE_DISABLE;
    hspi2.Init.CRCCalculation             = SPI_CRCCALCULATION_DISABLE;
    hspi2.Init.CRCPolynomial              = 0x0;
    hspi2.Init.NSSPMode                   = SPI_NSS_PULSE_DISABLE;
    hspi2.Init.NSSPolarity                = SPI_NSS_POLARITY_LOW;
    hspi2.Init.FifoThreshold              = SPI_FIFO_THRESHOLD_01DATA;
    hspi2.Init.TxCRCInitializationPattern = SPI_CRC_INITIALIZATION_ALL_ZERO_PATTERN;
    hspi2.Init.RxCRCInitializationPattern = SPI_CRC_INITIALIZATION_ALL_ZERO_PATTERN;
    hspi2.Init.MasterSSIdleness           = SPI_MASTER_SS_IDLENESS_00CYCLE;
    hspi2.Init.MasterInterDataIdleness    = SPI_MASTER_INTERDATA_IDLENESS_00CYCLE;
    hspi2.Init.MasterReceiverAutoSusp     = SPI_MASTER_RX_AUTOSUSP_DISABLE;
    hspi2.Init.MasterKeepIOState          = SPI_MASTER_KEEP_IO_STATE_DISABLE;
    hspi2.Init.IOSwap                     = SPI_IO_SWAP_DISABLE;
    if (HAL_SPI_Init(&hspi2) != HAL_OK)
    {
        Error_Handler();
    }
}

static void MX_TIM3_Init(void)
{

    TIM_MasterConfigTypeDef sMasterConfig = { 0 };
    TIM_OC_InitTypeDef      sConfigOC     = { 0 };

    htim3.Instance               = TIM3;
    htim3.Init.Prescaler         = TIM3_PRESCALER - 1;
    htim3.Init.CounterMode       = TIM_COUNTERMODE_UP;
    htim3.Init.Period            = (TIMx_FREQUENCY / TIM3_PRESCALER / ADC_FREQUENCY) - 1;
    htim3.Init.ClockDivision     = TIM_CLOCKDIVISION_DIV1;
    htim3.Init.AutoReloadPreload = TIM_AUTORELOAD_PRELOAD_DISABLE;
    if (HAL_TIM_OC_Init(&htim3) != HAL_OK)
    {
        Error_Handler();
    }
    sMasterConfig.MasterOutputTrigger = TIM_TRGO_UPDATE;
    sMasterConfig.MasterSlaveMode     = TIM_MASTERSLAVEMODE_DISABLE;
    if (HAL_TIMEx_MasterConfigSynchronization(&htim3, &sMasterConfig) != HAL_OK)
    {
        Error_Handler();
    }
    sConfigOC.OCMode     = TIM_OCMODE_TIMING;
    sConfigOC.Pulse      = 0;
    sConfigOC.OCPolarity = TIM_OCPOLARITY_HIGH;
    sConfigOC.OCFastMode = TIM_OCFAST_DISABLE;
    if (HAL_TIM_OC_ConfigChannel(&htim3, &sConfigOC, TIM_CHANNEL_1) != HAL_OK)
    {
        Error_Handler();
    }
}

static void MX_TIM7_Init(void)
{

    TIM_MasterConfigTypeDef sMasterConfig = { 0 };

    htim7.Instance               = TIM7;
    htim7.Init.Prescaler         = 10 - 1;
    htim7.Init.CounterMode       = TIM_COUNTERMODE_UP;
    htim7.Init.Period            = 960 - 1;
    htim7.Init.AutoReloadPreload = TIM_AUTORELOAD_PRELOAD_DISABLE;
    if (HAL_TIM_Base_Init(&htim7) != HAL_OK)
    {
        Error_Handler();
    }
    sMasterConfig.MasterOutputTrigger = TIM_TRGO_RESET;
    sMasterConfig.MasterSlaveMode     = TIM_MASTERSLAVEMODE_DISABLE;
    if (HAL_TIMEx_MasterConfigSynchronization(&htim7, &sMasterConfig) != HAL_OK)
    {
        Error_Handler();
    }
}

static void MX_UART8_Init(void)
{

    huart8.Instance                    = UART8;
    huart8.Init.BaudRate               = SBG_ELLIPSE_GPS_BAUD_RATE;
    huart8.Init.WordLength             = UART_WORDLENGTH_8B;
    huart8.Init.StopBits               = UART_STOPBITS_1;
    huart8.Init.Parity                 = UART_PARITY_NONE;
    huart8.Init.Mode                   = UART_MODE_TX_RX;
    huart8.Init.HwFlowCtl              = UART_HWCONTROL_NONE;
    huart8.Init.OverSampling           = UART_OVERSAMPLING_16;
    huart8.Init.OneBitSampling         = UART_ONE_BIT_SAMPLE_DISABLE;
    huart8.Init.ClockPrescaler         = UART_PRESCALER_DIV1;
    huart8.AdvancedInit.AdvFeatureInit = UART_ADVFEATURE_NO_INIT;
    if (HAL_UART_Init(&huart8) != HAL_OK)
    {
        Error_Handler();
    }
    if (HAL_UARTEx_SetTxFifoThreshold(&huart8, UART_TXFIFO_THRESHOLD_1_8) != HAL_OK)
    {
        Error_Handler();
    }
    if (HAL_UARTEx_SetRxFifoThreshold(&huart8, UART_RXFIFO_THRESHOLD_1_8) != HAL_OK)
    {
        Error_Handler();
    }
    if (HAL_UARTEx_DisableFifoMode(&huart8) != HAL_OK)
    {
        Error_Handler();
    }
}

static void MX_USB_OTG_HS_PCD_Init(void)
{

    hpcd_USB_OTG_HS.Instance                 = USB_OTG_HS;
    hpcd_USB_OTG_HS.Init.dev_endpoints       = 9;
    hpcd_USB_OTG_HS.Init.speed               = PCD_SPEED_FULL;
    hpcd_USB_OTG_HS.Init.dma_enable          = DISABLE;
    hpcd_USB_OTG_HS.Init.phy_itface          = USB_OTG_EMBEDDED_PHY;
    hpcd_USB_OTG_HS.Init.Sof_enable          = DISABLE;
    hpcd_USB_OTG_HS.Init.low_power_enable    = DISABLE;
    hpcd_USB_OTG_HS.Init.lpm_enable          = DISABLE;
    hpcd_USB_OTG_HS.Init.vbus_sensing_enable = DISABLE;
    hpcd_USB_OTG_HS.Init.use_dedicated_ep1   = DISABLE;
    hpcd_USB_OTG_HS.Init.use_external_vbus   = DISABLE;
    if (HAL_PCD_Init(&hpcd_USB_OTG_HS) != HAL_OK)
    {
        Error_Handler();
    }
}

static void MX_DMA_Init(void)
{
    /* DMA controller clock enable */
    __HAL_RCC_DMA1_CLK_ENABLE();

    /* DMA interrupt init */
    /* DMA1_Stream0_IRQn interrupt configuration */
    HAL_NVIC_SetPriority(DMA1_Stream0_IRQn, 5, 0);
    HAL_NVIC_EnableIRQ(DMA1_Stream0_IRQn);
    /* DMA1_Stream1_IRQn interrupt configuration */
    HAL_NVIC_SetPriority(DMA1_Stream1_IRQn, 5, 0);
    HAL_NVIC_EnableIRQ(DMA1_Stream1_IRQn);
    /* DMA1_Stream2_IRQn interrupt configuration */
    HAL_NVIC_SetPriority(DMA1_Stream2_IRQn, 5, 0);
    HAL_NVIC_EnableIRQ(DMA1_Stream2_IRQn);
    /* DMA1_Stream3_IRQn interrupt configuration */
    HAL_NVIC_SetPriority(DMA1_Stream3_IRQn, 5, 0);
    HAL_NVIC_EnableIRQ(DMA1_Stream3_IRQn);
    /* DMA1_Stream5_IRQn interrupt configuration */
    HAL_NVIC_SetPriority(DMA1_Stream5_IRQn, 5, 0);
    HAL_NVIC_EnableIRQ(DMA1_Stream5_IRQn);
}

static void MX_GPIO_Init(void)
{
    GPIO_InitTypeDef GPIO_InitStruct = { 0 };

    /* GPIO Ports Clock Enable */
    __HAL_RCC_GPIOE_CLK_ENABLE();
    __HAL_RCC_GPIOC_CLK_ENABLE();
    __HAL_RCC_GPIOH_CLK_ENABLE();
    __HAL_RCC_GPIOA_CLK_ENABLE();
    __HAL_RCC_GPIOB_CLK_ENABLE();
    __HAL_RCC_GPIOD_CLK_ENABLE();

    /*Configure GPIO pin Output Level */
    HAL_GPIO_WritePin(
        GPIOE, IMU_CS1_Pin | IMU_CS2_Pin | IMU_CS3_Pin | LED_Pin | BOOT_Pin | IMU_FSYNC_Pin, GPIO_PIN_RESET);

    /*Configure GPIO pin Output Level */
    HAL_GPIO_WritePin(GPIOB, BAT_CHRG_nSHDN_Pin | BMS_EN_Pin | FRONT_EN_Pin | RL_PUMP_EN_Pin, GPIO_PIN_RESET);

    /*Configure GPIO pin Output Level */
    HAL_GPIO_WritePin(
        GPIOD, F_INV_EN_Pin | RSM_EN_Pin | R_INV_EN_Pin | MISC_FUSE_EN_Pin | R_RAD_FAN_EN_Pin | L_RAD_FAN_EN_Pin,
        GPIO_PIN_RESET);

    /*Configure GPIO pin Output Level */
    HAL_GPIO_WritePin(GPIOC, DAM_EN_Pin | PCM_EN_Pin, GPIO_PIN_RESET);

    /*Configure GPIO pin Output Level */
    HAL_GPIO_WritePin(RR_PUMP_EN_GPIO_Port, RR_PUMP_EN_Pin, GPIO_PIN_RESET);

    /*Configure GPIO pins : IMU_CS1_Pin IMU_CS2_Pin IMU_CS3_Pin LED_Pin
                             BOOT_Pin IMU_FSYNC_Pin */
    GPIO_InitStruct.Pin   = IMU_CS1_Pin | IMU_CS2_Pin | IMU_CS3_Pin | LED_Pin | BOOT_Pin | IMU_FSYNC_Pin;
    GPIO_InitStruct.Mode  = GPIO_MODE_OUTPUT_PP;
    GPIO_InitStruct.Pull  = GPIO_NOPULL;
    GPIO_InitStruct.Speed = GPIO_SPEED_FREQ_LOW;
    HAL_GPIO_Init(GPIOE, &GPIO_InitStruct);

    /*Configure GPIO pins : IMU_INT1_Pin IMU_INT2_Pin */
    GPIO_InitStruct.Pin  = IMU_INT1_Pin | IMU_INT2_Pin;
    GPIO_InitStruct.Mode = GPIO_MODE_IT_RISING;
    GPIO_InitStruct.Pull = GPIO_NOPULL;
    HAL_GPIO_Init(GPIOE, &GPIO_InitStruct);

    /*Configure GPIO pin : IMU_INT3_Pin */
    GPIO_InitStruct.Pin  = IMU_INT3_Pin;
    GPIO_InitStruct.Mode = GPIO_MODE_IT_RISING;
    GPIO_InitStruct.Pull = GPIO_NOPULL;
    HAL_GPIO_Init(IMU_INT3_GPIO_Port, &GPIO_InitStruct);

    /*Configure GPIO pins : TSMS_3V3_OUT_Pin FRONT_PG_Pin RL_PUMP_PGOOD_Pin */
    GPIO_InitStruct.Pin  = TSMS_3V3_OUT_Pin | FRONT_PG_Pin | RL_PUMP_PGOOD_Pin;
    GPIO_InitStruct.Mode = GPIO_MODE_INPUT;
    GPIO_InitStruct.Pull = GPIO_NOPULL;
    HAL_GPIO_Init(GPIOB, &GPIO_InitStruct);

    /*Configure GPIO pins : RR_ILCK_3V3_OUT_Pin BMS_PG_Pin INERTIA_3V3_OUT_Pin PWR_MTR_nALERT_Pin
                             BOOST_PG_Pin BAT_CHRG_MODE_Pin */
    GPIO_InitStruct.Pin =
        RR_ILCK_3V3_OUT_Pin | BMS_PG_Pin | INERTIA_3V3_OUT_Pin | PWR_MTR_nALERT_Pin | BOOST_PG_Pin | BAT_CHRG_MODE_Pin;
    GPIO_InitStruct.Mode = GPIO_MODE_INPUT;
    GPIO_InitStruct.Pull = GPIO_NOPULL;
    HAL_GPIO_Init(GPIOE, &GPIO_InitStruct);

    /*Configure GPIO pins : BAT_CHRG_nSHDN_Pin BMS_EN_Pin FRONT_EN_Pin */
    GPIO_InitStruct.Pin   = BAT_CHRG_nSHDN_Pin | BMS_EN_Pin | FRONT_EN_Pin;
    GPIO_InitStruct.Mode  = GPIO_MODE_OUTPUT_PP;
    GPIO_InitStruct.Pull  = GPIO_NOPULL;
    GPIO_InitStruct.Speed = GPIO_SPEED_FREQ_LOW;
    HAL_GPIO_Init(GPIOB, &GPIO_InitStruct);

    /*Configure GPIO pin : BAT_MTR_nALERT_Pin */
    GPIO_InitStruct.Pin  = BAT_MTR_nALERT_Pin;
    GPIO_InitStruct.Mode = GPIO_MODE_IT_RISING;
    GPIO_InitStruct.Pull = GPIO_NOPULL;
    HAL_GPIO_Init(BAT_MTR_nALERT_GPIO_Port, &GPIO_InitStruct);

    /*Configure GPIO pins : R_INV_PG_Pin F_INV_PG_Pin SB_SHDN_3V3_OUT_Pin MISC_FUSE_PG_Pin
                             L_RAD_FAN_PG_Pin R_RAD_FAN_PG_Pin */
    GPIO_InitStruct.Pin =
        R_INV_PG_Pin | F_INV_PG_Pin | SB_SHDN_3V3_OUT_Pin | MISC_FUSE_PG_Pin | L_RAD_FAN_PG_Pin | R_RAD_FAN_PG_Pin;
    GPIO_InitStruct.Mode = GPIO_MODE_INPUT;
    GPIO_InitStruct.Pull = GPIO_NOPULL;
    HAL_GPIO_Init(GPIOD, &GPIO_InitStruct);

    /*Configure GPIO pins : F_INV_EN_Pin RSM_EN_Pin R_INV_EN_Pin MISC_FUSE_EN_Pin
                             R_RAD_FAN_EN_Pin L_RAD_FAN_EN_Pin */
    GPIO_InitStruct.Pin =
        F_INV_EN_Pin | RSM_EN_Pin | R_INV_EN_Pin | MISC_FUSE_EN_Pin | R_RAD_FAN_EN_Pin | L_RAD_FAN_EN_Pin;
    GPIO_InitStruct.Mode  = GPIO_MODE_OUTPUT_PP;
    GPIO_InitStruct.Pull  = GPIO_NOPULL;
    GPIO_InitStruct.Speed = GPIO_SPEED_FREQ_LOW;
    HAL_GPIO_Init(GPIOD, &GPIO_InitStruct);

    /*Configure GPIO pins : RSM_PG_Pin DAM_PG_Pin */
    GPIO_InitStruct.Pin  = RSM_PG_Pin | DAM_PG_Pin;
    GPIO_InitStruct.Mode = GPIO_MODE_INPUT;
    GPIO_InitStruct.Pull = GPIO_NOPULL;
    HAL_GPIO_Init(GPIOC, &GPIO_InitStruct);

    /*Configure GPIO pins : DAM_EN_Pin PCM_EN_Pin */
    GPIO_InitStruct.Pin   = DAM_EN_Pin | PCM_EN_Pin;
    GPIO_InitStruct.Mode  = GPIO_MODE_OUTPUT_PP;
    GPIO_InitStruct.Pull  = GPIO_NOPULL;
    GPIO_InitStruct.Speed = GPIO_SPEED_FREQ_LOW;
    HAL_GPIO_Init(GPIOC, &GPIO_InitStruct);

    /*Configure GPIO pin : RR_PUMP_EN_Pin */
    GPIO_InitStruct.Pin   = RR_PUMP_EN_Pin;
    GPIO_InitStruct.Mode  = GPIO_MODE_OUTPUT_OD;
    GPIO_InitStruct.Pull  = GPIO_NOPULL;
    GPIO_InitStruct.Speed = GPIO_SPEED_FREQ_LOW;
    HAL_GPIO_Init(RR_PUMP_EN_GPIO_Port, &GPIO_InitStruct);

    /*Configure GPIO pin : RR_PUMP_PGOOD_Pin */
    GPIO_InitStruct.Pin  = RR_PUMP_PGOOD_Pin;
    GPIO_InitStruct.Mode = GPIO_MODE_INPUT;
    GPIO_InitStruct.Pull = GPIO_NOPULL;
    HAL_GPIO_Init(RR_PUMP_PGOOD_GPIO_Port, &GPIO_InitStruct);

    /*Configure GPIO pin : RL_PUMP_EN_Pin */
    GPIO_InitStruct.Pin   = RL_PUMP_EN_Pin;
    GPIO_InitStruct.Mode  = GPIO_MODE_OUTPUT_OD;
    GPIO_InitStruct.Pull  = GPIO_NOPULL;
    GPIO_InitStruct.Speed = GPIO_SPEED_FREQ_LOW;
    HAL_GPIO_Init(RL_PUMP_EN_GPIO_Port, &GPIO_InitStruct);

    /* EXTI interrupt init*/
    HAL_NVIC_SetPriority(IMU_INT1_EXTI_IRQn, 5, 0);
    HAL_NVIC_EnableIRQ(IMU_INT1_EXTI_IRQn);

    HAL_NVIC_SetPriority(BAT_MTR_nALERT_EXTI_IRQn, 5, 0);
    HAL_NVIC_EnableIRQ(BAT_MTR_nALERT_EXTI_IRQn);

}

void HAL_TIM_PeriodElapsedCallback(TIM_HandleTypeDef *htim)
{
    if (htim->Instance == TIM6)
    {
        HAL_IncTick();
    }
}

void Error_Handler(void)
{
    __disable_irq();
    while (1)
    {
    }
}
